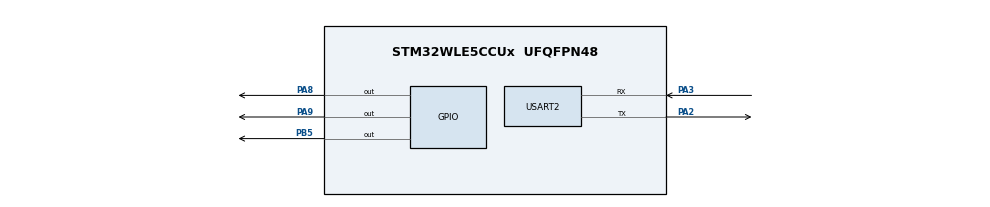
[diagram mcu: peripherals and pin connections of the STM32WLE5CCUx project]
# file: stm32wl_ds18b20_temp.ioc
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Mcu.Family=STM32WL
Mcu.Name=STM32WLE5CCUx
Mcu.Package=UFQFPN48
NVIC.PriorityGroup=NVIC_PRIORITYGROUP_4
PA2.Mode=Asynchronous
PA2.Signal=USART2_TX
PA3.Mode=Asynchronous
PA3.Signal=USART2_RX
PA8.Signal=GPIO_Output
PA9.Signal=GPIO_Output
PB5.Signal=GPIO_Output
PC14-OSC32_IN.Mode=LSE-External-Clock-Source
PC14-OSC32_IN.Signal=RCC_OSC32_IN
ProjectManager.HeapSize=0x200
ProjectManager.StackSize=0x400
ProjectManager.TargetToolchain=STM32CubeIDE
RCC.AHBFreq_Value=48000000
RCC.APB1CLKDivider=RCC_HCLK_DIV2
RCC.APB1Freq_Value=24000000
RCC.APB1TimFreq_Value=48000000
RCC.APB2Freq_Value=48000000
RCC.APB2TimFreq_Value=48000000
RCC.APB3Freq_Value=48000000
RCC.CortexFreq_Value=48000000
RCC.HCLKFreq_Value=48000000
RCC.HSE_VALUE=8000000
RCC.HSI_VALUE=16000000
RCC.LSE_VALUE=32768
RCC.PLLN=24
RCC.SYSCLKFreq_VALUE=48000000
RCC.SYSCLKSource=RCC_SYSCLKSOURCE_PLLCLK
RCC.VCOOutputFreq_Value=96000000
TIM2.Period=65535
TIM2.Prescaler=15
USART2.VirtualMode-Asynchronous=VM_ASYNC
VP_TIM1_VS_ClockSourceINT.Mode=Internal
VP_TIM2_VS_ClockSourceINT.Mode=Internal
board=custom

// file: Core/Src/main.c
/* USER CODE BEGIN Header */
/**
  ******************************************************************************
  * @file           : main.c
  * @brief          : DS18B20 Temperature Reading with DWT Delay (STM32WL)
  ******************************************************************************
  */
/* USER CODE END Header */
#include "main.h"
#include "ds18b20.h"

TIM_HandleTypeDef htim1;
TIM_HandleTypeDef htim2;

UART_HandleTypeDef huart2;

void SystemClock_Config(void);
static void MX_GPIO_Init(void);
static void MX_TIM2_Init(void);
static void MX_USART2_UART_Init(void);
static void MX_TIM1_Init(void);

int main(void)
{

  /* MCU Configuration--------------------------------------------------------*/

  /* Reset of all peripherals, Initializes the Flash interface and the Systick. */
  HAL_Init();

  /* Configure the system clock */
  SystemClock_Config();

  /* Initialize all configured peripherals */
  MX_GPIO_Init();
  MX_TIM2_Init();
  MX_USART2_UART_Init();
  MX_TIM1_Init();
  /* USER CODE BEGIN 2 */
  DS18B20_Init(&htim1, GPIOA, GPIO_PIN_8);
  /* USER CODE END 2 */
  char msg[50];
  sprintf(msg, "Temp: device onC\r\n");
  HAL_UART_Transmit(&huart2, (uint8_t*)msg, strlen(msg), HAL_MAX_DELAY);
  /* Infinite loop */
  while (1)
  {
	    float temp = DS18B20_ReadTemp();
	    sprintf(msg, "Temp: %.2f C\r\n", temp);
	    HAL_UART_Transmit(&huart2, (uint8_t*)msg, strlen(msg), HAL_MAX_DELAY);
	    HAL_Delay(1000);
  }
}

void SystemClock_Config(void)
{
  RCC_OscInitTypeDef RCC_OscInitStruct = {0};
  RCC_ClkInitTypeDef RCC_ClkInitStruct = {0};

  /** Configure the main internal regulator output voltage
  */
  __HAL_PWR_VOLTAGESCALING_CONFIG(PWR_REGULATOR_VOLTAGE_SCALE1);

  /** Initializes the CPU, AHB and APB buses clocks
  */
  RCC_OscInitStruct.OscillatorType = RCC_OSCILLATORTYPE_LSE|RCC_OSCILLATORTYPE_MSI;
  RCC_OscInitStruct.LSEState = RCC_LSE_BYPASS;
  RCC_OscInitStruct.MSIState = RCC_MSI_ON;
  RCC_OscInitStruct.MSICalibrationValue = RCC_MSICALIBRATION_DEFAULT;
  RCC_OscInitStruct.MSIClockRange = RCC_MSIRANGE_6;
  RCC_OscInitStruct.PLL.PLLState = RCC_PLL_ON;
  RCC_OscInitStruct.PLL.PLLSource = RCC_PLLSOURCE_MSI;
  RCC_OscInitStruct.PLL.PLLM = RCC_PLLM_DIV1;
  RCC_OscInitStruct.PLL.PLLN = 24;
  RCC_OscInitStruct.PLL.PLLP = RCC_PLLP_DIV2;
  RCC_OscInitStruct.PLL.PLLR = RCC_PLLR_DIV2;
  RCC_OscInitStruct.PLL.PLLQ = RCC_PLLQ_DIV2;
  if (HAL_RCC_OscConfig(&RCC_OscInitStruct) != HAL_OK)
  {
    Error_Handler();
  }

  /** Configure the SYSCLKSource, HCLK, PCLK1 and PCLK2 clocks dividers
  */
  RCC_ClkInitStruct.ClockType = RCC_CLOCKTYPE_HCLK3|RCC_CLOCKTYPE_HCLK
                              |RCC_CLOCKTYPE_SYSCLK|RCC_CLOCKTYPE_PCLK1
                              |RCC_CLOCKTYPE_PCLK2;
  RCC_ClkInitStruct.SYSCLKSource = RCC_SYSCLKSOURCE_PLLCLK;
  RCC_ClkInitStruct.AHBCLKDivider = RCC_SYSCLK_DIV1;
  RCC_ClkInitStruct.APB1CLKDivider = RCC_HCLK_DIV2;
  RCC_ClkInitStruct.APB2CLKDivider = RCC_HCLK_DIV1;
  RCC_ClkInitStruct.AHBCLK3Divider = RCC_SYSCLK_DIV1;

  if (HAL_RCC_ClockConfig(&RCC_ClkInitStruct, FLASH_LATENCY_2) != HAL_OK)
  {
    Error_Handler();
  }
}

static void MX_TIM1_Init(void)
{

  TIM_ClockConfigTypeDef sClockSourceConfig = {0};
  TIM_MasterConfigTypeDef sMasterConfig = {0};

  htim1.Instance = TIM1;
  htim1.Init.Prescaler = 0;
  htim1.Init.CounterMode = TIM_COUNTERMODE_UP;
  htim1.Init.Period = 65535;
  htim1.Init.ClockDivision = TIM_CLOCKDIVISION_DIV1;
  htim1.Init.RepetitionCounter = 0;
  htim1.Init.AutoReloadPreload = TIM_AUTORELOAD_PRELOAD_DISABLE;
  if (HAL_TIM_Base_Init(&htim1) != HAL_OK)
  {
    Error_Handler();
  }
  sClockSourceConfig.ClockSource = TIM_CLOCKSOURCE_INTERNAL;
  if (HAL_TIM_ConfigClockSource(&htim1, &sClockSourceConfig) != HAL_OK)
  {
    Error_Handler();
  }
  sMasterConfig.MasterOutputTrigger = TIM_TRGO_RESET;
  sMasterConfig.MasterOutputTrigger2 = TIM_TRGO2_RESET;
  sMasterConfig.MasterSlaveMode = TIM_MASTERSLAVEMODE_DISABLE;
  if (HAL_TIMEx_MasterConfigSynchronization(&htim1, &sMasterConfig) != HAL_OK)
  {
    Error_Handler();
  }

}

static void MX_TIM2_Init(void)
{

  TIM_ClockConfigTypeDef sClockSourceConfig = {0};
  TIM_MasterConfigTypeDef sMasterConfig = {0};

  htim2.Instance = TIM2;
  htim2.Init.Prescaler = 47;
  htim2.Init.CounterMode = TIM_COUNTERMODE_UP;
  htim2.Init.Period = 65535;
  htim2.Init.ClockDivision = TIM_CLOCKDIVISION_DIV1;
  htim2.Init.AutoReloadPreload = TIM_AUTORELOAD_PRELOAD_DISABLE;
  if (HAL_TIM_Base_Init(&htim2) != HAL_OK)
  {
    Error_Handler();
  }
  sClockSourceConfig.ClockSource = TIM_CLOCKSOURCE_INTERNAL;
  if (HAL_TIM_ConfigClockSource(&htim2, &sClockSourceConfig) != HAL_OK)
  {
    Error_Handler();
  }
  sMasterConfig.MasterOutputTrigger = TIM_TRGO_RESET;
  sMasterConfig.MasterSlaveMode = TIM_MASTERSLAVEMODE_DISABLE;
  if (HAL_TIMEx_MasterConfigSynchronization(&htim2, &sMasterConfig) != HAL_OK)
  {
    Error_Handler();
  }

}

static void MX_USART2_UART_Init(void)
{

  huart2.Instance = USART2;
  huart2.Init.BaudRate = 115200;
  huart2.Init.WordLength = UART_WORDLENGTH_8B;
  huart2.Init.StopBits = UART_STOPBITS_1;
  huart2.Init.Parity = UART_PARITY_NONE;
  huart2.Init.Mode = UART_MODE_TX_RX;
  huart2.Init.HwFlowCtl = UART_HWCONTROL_NONE;
  huart2.Init.OverSampling = UART_OVERSAMPLING_16;
  huart2.Init.OneBitSampling = UART_ONE_BIT_SAMPLE_DISABLE;
  huart2.Init.ClockPrescaler = UART_PRESCALER_DIV1;
  huart2.AdvancedInit.AdvFeatureInit = UART_ADVFEATURE_NO_INIT;
  if (HAL_UART_Init(&huart2) != HAL_OK)
  {
    Error_Handler();
  }
  if (HAL_UARTEx_SetTxFifoThreshold(&huart2, UART_TXFIFO_THRESHOLD_1_8) != HAL_OK)
  {
    Error_Handler();
  }
  if (HAL_UARTEx_SetRxFifoThreshold(&huart2, UART_RXFIFO_THRESHOLD_1_8) != HAL_OK)
  {
    Error_Handler();
  }
  if (HAL_UARTEx_DisableFifoMode(&huart2) != HAL_OK)
  {
    Error_Handler();
  }

}

static void MX_GPIO_Init(void)
{
  GPIO_InitTypeDef GPIO_InitStruct = {0};

  /* GPIO Ports Clock Enable */
  __HAL_RCC_GPIOB_CLK_ENABLE();
  __HAL_RCC_GPIOA_CLK_ENABLE();
  __HAL_RCC_GPIOC_CLK_ENABLE();

  /*Configure GPIO pin Output Level */
  HAL_GPIO_WritePin(GPIOB, GPIO_PIN_5, GPIO_PIN_RESET);

  /*Configure GPIO pin Output Level */
  HAL_GPIO_WritePin(GPIOA, GPIO_PIN_8|GPIO_PIN_9, GPIO_PIN_RESET);

  /*Configure GPIO pin : PB5 */
  GPIO_InitStruct.Pin = GPIO_PIN_5;
  GPIO_InitStruct.Mode = GPIO_MODE_OUTPUT_PP;
  GPIO_InitStruct.Pull = GPIO_NOPULL;
  GPIO_InitStruct.Speed = GPIO_SPEED_FREQ_LOW;
  HAL_GPIO_Init(GPIOB, &GPIO_InitStruct);

  /*Configure GPIO pins : PA8 PA9 */
  GPIO_InitStruct.Pin = GPIO_PIN_8|GPIO_PIN_9;
  GPIO_InitStruct.Mode = GPIO_MODE_OUTPUT_PP;
  GPIO_InitStruct.Pull = GPIO_NOPULL;
  GPIO_InitStruct.Speed = GPIO_SPEED_FREQ_LOW;
  HAL_GPIO_Init(GPIOA, &GPIO_InitStruct);

}

void Error_Handler(void)
{
  __disable_irq();
  while (1)
  {
  }
}
